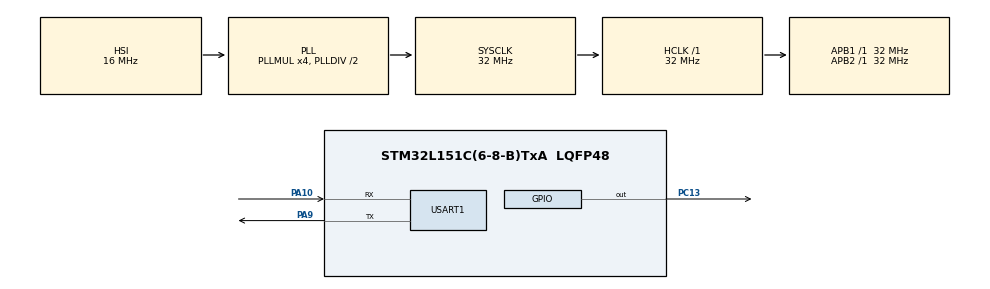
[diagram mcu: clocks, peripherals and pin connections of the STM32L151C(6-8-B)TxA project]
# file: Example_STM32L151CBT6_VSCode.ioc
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Mcu.Family=STM32L1
Mcu.Name=STM32L151C(6-8-B)TxA
Mcu.Package=LQFP48
NVIC.PriorityGroup=NVIC_PRIORITYGROUP_4
PA10.Mode=Asynchronous
PA10.Signal=USART1_RX
PA13.Mode=Serial_Wire
PA13.Signal=SYS_JTMS-SWDIO
PA14.Mode=Serial_Wire
PA14.Signal=SYS_JTCK-SWCLK
PA9.Mode=Asynchronous
PA9.Signal=USART1_TX
PC13-WKUP2.Signal=GPIO_Output
PH0-OSC_IN.Mode=HSE-External-Oscillator
PH0-OSC_IN.Signal=RCC_OSC_IN
PH1-OSC_OUT.Mode=HSE-External-Oscillator
PH1-OSC_OUT.Signal=RCC_OSC_OUT
ProjectManager.HeapSize=0x200
ProjectManager.StackSize=0x400
ProjectManager.TargetToolchain=STM32CubeIDE
RCC.48MHZClocksFreq_Value=32000000
RCC.AHBFreq_Value=32000000
RCC.APB1Freq_Value=32000000
RCC.APB1TimFreq_Value=32000000
RCC.APB2Freq_Value=32000000
RCC.APB2TimFreq_Value=32000000
RCC.HCLKFreq_Value=32000000
RCC.HSE_VALUE=24000000
RCC.HSI_VALUE=16000000
RCC.LSE_VALUE=32768
RCC.MSI_VALUE=2097000
RCC.PLLMUL=RCC_PLL_MUL4
RCC.SYSCLKFreq_VALUE=32000000
RCC.SYSCLKSource=RCC_SYSCLKSOURCE_PLLCLK
RCC.VCOOutputFreq_Value=64000000
USART1.VirtualMode=VM_ASYNC
board=custom

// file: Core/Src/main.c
/* USER CODE BEGIN Header */
/**
 ******************************************************************************
 * @file           : main.c
 * @brief          : Main program body
 ******************************************************************************
 * @attention
 *
 * <h2><center>&copy; Copyright (c) 2025 STMicroelectronics.
 * All rights reserved.</center></h2>
 *
 * This software component is licensed by ST under BSD 3-Clause license,
 * the "License"; You may not use this file except in compliance with the
 * License. You may obtain a copy of the License at:
 *                        opensource.org/licenses/BSD-3-Clause
 *
 ******************************************************************************
 */
/* USER CODE END Header */
#include "main.h"

/* USER CODE BEGIN Includes */
#include <stdio.h>
#include <string.h>

uint32_t Counter = 0;
unsigned char Tx_data[256] = {
    0,
};

/* USER CODE END Includes */

UART_HandleTypeDef huart1;

void SystemClock_Config(void);
static void MX_GPIO_Init(void);
static void MX_USART1_UART_Init(void);

int main(void) {

    /* MCU Configuration--------------------------------------------------------*/

    /* Reset of all peripherals, Initializes the Flash interface and the Systick. */
    HAL_Init();

    /* Configure the system clock */
    SystemClock_Config();

    /* Initialize all configured peripherals */
    MX_GPIO_Init();
    MX_USART1_UART_Init();

    /* Infinite loop */
    while (1) {

        /* USER CODE BEGIN 3 */
        GPIOC->BSRR = GPIO_BSRR_BR_13;
        HAL_Delay(100);
        GPIOC->BSRR = GPIO_BSRR_BS_13;
        HAL_Delay(100);
        HAL_UART_Transmit(&huart1, (unsigned char *)Tx_data, sprintf((char*)Tx_data, "Counter = %ld\r\n", Counter), 100);
        Counter++;
    }
    /* USER CODE END 3 */
}

void SystemClock_Config(void) {
    RCC_OscInitTypeDef RCC_OscInitStruct = {0};
    RCC_ClkInitTypeDef RCC_ClkInitStruct = {0};

    /** Configure the main internal regulator output voltage
     */
    __HAL_PWR_VOLTAGESCALING_CONFIG(PWR_REGULATOR_VOLTAGE_SCALE1);
    /** Initializes the RCC Oscillators according to the specified parameters
     * in the RCC_OscInitTypeDef structure.
     */
    RCC_OscInitStruct.OscillatorType = RCC_OSCILLATORTYPE_HSI;
    RCC_OscInitStruct.HSIState = RCC_HSI_ON;
    RCC_OscInitStruct.HSICalibrationValue = RCC_HSICALIBRATION_DEFAULT;
    RCC_OscInitStruct.PLL.PLLState = RCC_PLL_ON;
    RCC_OscInitStruct.PLL.PLLSource = RCC_PLLSOURCE_HSI;
    RCC_OscInitStruct.PLL.PLLMUL = RCC_PLL_MUL4;
    RCC_OscInitStruct.PLL.PLLDIV = RCC_PLL_DIV2;
    if (HAL_RCC_OscConfig(&RCC_OscInitStruct) != HAL_OK) {
        Error_Handler();
    }
    /** Initializes the CPU, AHB and APB buses clocks
     */
    RCC_ClkInitStruct.ClockType = RCC_CLOCKTYPE_HCLK | RCC_CLOCKTYPE_SYSCLK | RCC_CLOCKTYPE_PCLK1 | RCC_CLOCKTYPE_PCLK2;
    RCC_ClkInitStruct.SYSCLKSource = RCC_SYSCLKSOURCE_PLLCLK;
    RCC_ClkInitStruct.AHBCLKDivider = RCC_SYSCLK_DIV1;
    RCC_ClkInitStruct.APB1CLKDivider = RCC_HCLK_DIV1;
    RCC_ClkInitStruct.APB2CLKDivider = RCC_HCLK_DIV1;

    if (HAL_RCC_ClockConfig(&RCC_ClkInitStruct, FLASH_LATENCY_1) != HAL_OK) {
        Error_Handler();
    }
}

static void MX_USART1_UART_Init(void) {

    huart1.Instance = USART1;
    huart1.Init.BaudRate = 115200;
    huart1.Init.WordLength = UART_WORDLENGTH_8B;
    huart1.Init.StopBits = UART_STOPBITS_1;
    huart1.Init.Parity = UART_PARITY_NONE;
    huart1.Init.Mode = UART_MODE_TX_RX;
    huart1.Init.HwFlowCtl = UART_HWCONTROL_NONE;
    huart1.Init.OverSampling = UART_OVERSAMPLING_16;
    if (HAL_UART_Init(&huart1) != HAL_OK) {
        Error_Handler();
    }
}

static void MX_GPIO_Init(void) {
    GPIO_InitTypeDef GPIO_InitStruct = {0};

    /* GPIO Ports Clock Enable */
    __HAL_RCC_GPIOC_CLK_ENABLE();
    __HAL_RCC_GPIOH_CLK_ENABLE();
    __HAL_RCC_GPIOA_CLK_ENABLE();

    /*Configure GPIO pin Output Level */
    HAL_GPIO_WritePin(GPIOC, GPIO_PIN_13, GPIO_PIN_RESET);

    /*Configure GPIO pin : PC13 */
    GPIO_InitStruct.Pin = GPIO_PIN_13;
    GPIO_InitStruct.Mode = GPIO_MODE_OUTPUT_PP;
    GPIO_InitStruct.Pull = GPIO_NOPULL;
    GPIO_InitStruct.Speed = GPIO_SPEED_FREQ_LOW;
    HAL_GPIO_Init(GPIOC, &GPIO_InitStruct);
}

void Error_Handler(void) {
    __disable_irq();
    while (1) {
    }
}

/************************ (C) COPYRIGHT STMicroelectronics *****END OF FILE****/
